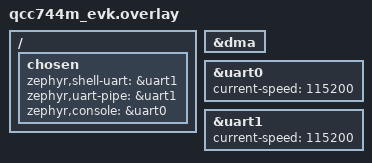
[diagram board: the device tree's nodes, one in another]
/* 
 * Copyright (c) 2026 Qualcomm Technologies, Inc. and/or its subsidiaries
 * SPDX-License-Identifier: BSD-3-Clause
 */

/* 
 * Please connect UART1 TX and UART1 RX for this test case.
 */

/ {
	chosen {
		/* UART1 has DMA support */
		zephyr,shell-uart = &uart1;
		zephyr,uart-pipe = &uart1;
		/* UART0 for console only (polling mode) */
		zephyr,console = &uart0;
	};
};

&dma {
	status = "okay";
};

&uart0 {
	status = "okay";
	current-speed = <115200>;
};

&uart1 {
	status = "okay";
	current-speed = <115200>;
};
